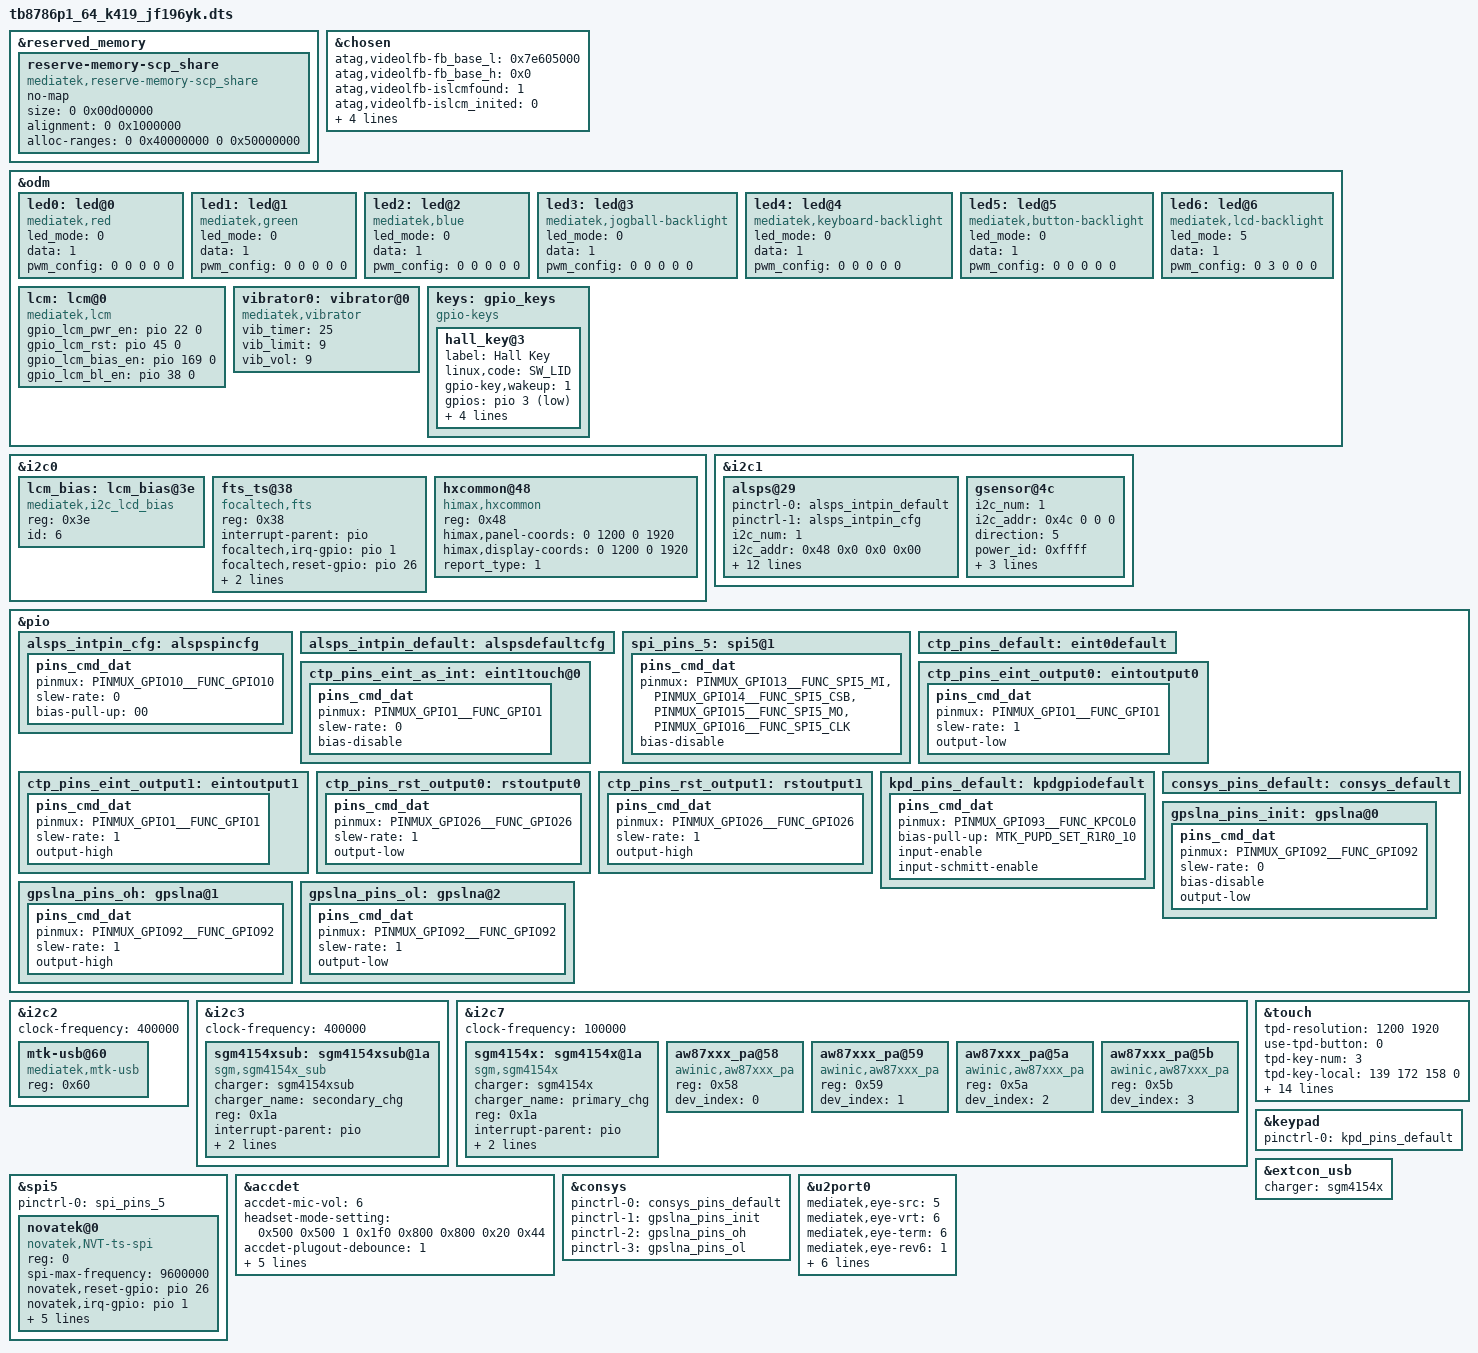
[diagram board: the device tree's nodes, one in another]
// SPDX-License-Identifier: GPL-2.0
/*
 * Copyright (c) 2019 MediaTek Inc.
 */

/dts-v1/;
/plugin/;
#include <dt-bindings/interrupt-controller/irq.h>
#include <dt-bindings/interrupt-controller/arm-gic.h>
#include <dt-bindings/pinctrl/mt6768-pinfunc.h>
#include <dt-bindings/input/input.h>

&reserved_memory {
	reserve-memory-scp_share {
		compatible = "mediatek,reserve-memory-scp_share";
		no-map;
		size = <0 0x00d00000>;
		alignment = <0 0x1000000>;
		alloc-ranges = <0 0x40000000 0 0x50000000>;
	};
};

/* chosen */
&chosen {

	atag,videolfb-fb_base_l = <0x7e605000>;
	atag,videolfb-fb_base_h = <0x0>;
	atag,videolfb-islcmfound = <1>;
	atag,videolfb-islcm_inited = <0>;
	atag,videolfb-fps= <6000>;
	atag,videolfb-vramSize= <0x017e8000>;
	atag,videolfb-lcmname=
		"hx83112b_fhdp_dsi_cmd_auo_rt5081_drv";
};

&odm {
	led0:led@0 {
		compatible = "mediatek,red";
		led_mode = <0>;
		data = <1>;
		pwm_config = <0 0 0 0 0>;
	};
	led1:led@1 {
		compatible = "mediatek,green";
		led_mode = <0>;
		data = <1>;
		pwm_config = <0 0 0 0 0>;
	};
	led2:led@2 {
		compatible = "mediatek,blue";
		led_mode = <0>;
		data = <1>;
		pwm_config = <0 0 0 0 0>;
	};
	led3:led@3 {
		compatible = "mediatek,jogball-backlight";
		led_mode = <0>;
		data = <1>;
		pwm_config = <0 0 0 0 0>;
	};
	led4:led@4 {
		compatible = "mediatek,keyboard-backlight";
		led_mode = <0>;
		data = <1>;
		pwm_config = <0 0 0 0 0>;
	};
	led5:led@5 {
		compatible = "mediatek,button-backlight";
		led_mode = <0>;
		data = <1>;
		pwm_config = <0 0 0 0 0>;
	};
	led6:led@6 {
		compatible = "mediatek,lcd-backlight";
		led_mode = <5>;
		data = <1>;
		pwm_config = <0 3 0 0 0>;
	};
	
	lcm: lcm@0{
		compatible = "mediatek,lcm";
		gpio_lcm_pwr_en = <&pio 22 0>; 			/*3.3V  1.8v*/
		gpio_lcm_rst = <&pio 45 0>;				//reset
		gpio_lcm_bias_en = <&pio 169 0>;
		gpio_lcm_bl_en = <&pio 38 0>;
		status = "okay";
	};
	
	vibrator0:vibrator@0 {
		compatible = "mediatek,vibrator";
		vib_timer = <25>;
		vib_limit = <9>;
		vib_vol= <9>;
	};
	
    keys: gpio_keys{         
		compatible = "gpio-keys";
		hall_key@3 {
			   label = "Hall Key";
			   linux,code = <SW_LID>;
			   gpio-key,wakeup = <1>;
			   gpios = <&pio 3 1>;
			   linux,input-type = <EV_SW>;
			   interrupt-parent = <&pio>;
			   interrupts = <3 IRQ_TYPE_EDGE_BOTH 3 0>;
			   debounce-interval = <20>;
		};
    };
};

&i2c0 {
	
	lcm_bias: lcm_bias@3e {
		compatible = "mediatek,i2c_lcd_bias";
		reg = <0x3e>;
		id = <6>;
		status = "okay";
	};
	
	fts_ts@38 {
		compatible = "focaltech,fts";
		reg = <0x38>;
		interrupt-parent = <&pio>;
		focaltech,irq-gpio = <&pio 1 0>;
		focaltech,reset-gpio = <&pio 26 0>;
		focaltech,max-touch-number = <10>;
		focaltech,display-coords =  <0 0 1200 1920>;
	};

	hxcommon@48 {
		compatible = "himax,hxcommon";
		reg = <0x48>;

		himax,panel-coords = <0 1200 0 1920>;
		himax,display-coords = <0 1200 0 1920>;

		status = "okay";
		report_type = <1>;
	};

};

&i2c1 {
	
	alsps@29 {
		pinctrl-names = "pin_default", "pin_cfg";
		pinctrl-0 = <&alsps_intpin_default>;
		pinctrl-1 = <&alsps_intpin_cfg>;
		status = "okay";
		/* customization */
		i2c_num = <1>;
		i2c_addr = <0x48 0x0 0x0 0x00>;
		polling_mode_ps = <0>;
		polling_mode_als = <1>;
		power_id = <0xffff>;
		power_vol = <0>;
		als_level =
			<0 1 1 7 15 15 100 1000 2000 3000
			6000 10000 14000 18000 20000>;
		als_value =
			<40 40 90 90 160 160 225 320 640 1280
			1280 2600 2600 2600 10240 10240>;
		ps_threshold_high = <900>;
		ps_threshold_low = <600>;
		is_batch_supported_ps = <0>;
		is_batch_supported_als = <0>;
	};	
	gsensor@4c{
		i2c_num = <1>;
		i2c_addr = <0x4c 0 0 0>;
		direction = <5>;
		power_id = <0xffff>;
		power_vol = <0>;
		firlen = <16>;
		is_batch_supported = <0>;
	};
	
};

&pio {
	alsps_intpin_cfg: alspspincfg {
	    pins_cmd_dat {
			pinmux = <PINMUX_GPIO10__FUNC_GPIO10>;
			slew-rate = <0>;
			bias-pull-up = <00>;
		};
	};

	alsps_intpin_default: alspsdefaultcfg {

	};
};

&i2c2 {
	clock-frequency = <400000>;

	mtk-usb@60 {
		compatible = "mediatek,mtk-usb";
		reg = <0x60>;
		status = "okay";
	};
};

&i2c3 {
	clock-frequency = <400000>;


	sgm4154xsub: sgm4154xsub@1a{
	  charger = <&sgm4154xsub>;
	  status = "okay";
	  compatible = "sgm,sgm4154x_sub";
	  charger_name = "secondary_chg";
	  reg = <0x1a>;
	  interrupt-parent = <&pio>;   
	  /*interrupts = <0 0>;*/						//irq num base on hardware design  
	  sgm,irq-gpio = <&pio 8 0>;        		 //irq num base on hardware design
	  sgm,chg-en-gpio = <&pio 6 0>;   		 //gpio num base on hardware design
	};
};

&i2c7 {
	clock-frequency = <100000>;

	sgm4154x: sgm4154x@1a{
	  charger = <&sgm4154x>;
	  status = "okay";
	  compatible = "sgm,sgm4154x";
	  charger_name = "primary_chg";
	  reg = <0x1a>;
	  interrupt-parent = <&pio>;
	  /*interrupts = <0 0>;*/						//irq num base on hardware design  
	  sgm,irq-gpio = <&pio 20 0>;        		 //irq num base on hardware design
	  sgm,chg-en-gpio = <&pio 166 0>;   		 //gpio num base on hardware design
	};
	
	aw87xxx_pa@58 {
        compatible = "awinic,aw87xxx_pa";
        reg = <0x58>;
        dev_index = < 0 >;
        status = "okay";
    };

    aw87xxx_pa@59 {
        compatible = "awinic,aw87xxx_pa";
        reg = <0x59>;
        dev_index = < 1 >;
        status = "okay";
    };

    aw87xxx_pa@5a {
        compatible = "awinic,aw87xxx_pa";
        reg = <0x5a>;
        dev_index = < 2 >;
        status = "okay";
    };
    aw87xxx_pa@5b {
        compatible = "awinic,aw87xxx_pa";
        reg = <0x5b>;
        dev_index = < 3 >;
        status = "okay";
    };

};

&pio{
    spi_pins_5:spi5@1{
        pins_cmd_dat{
            pinmux = <PINMUX_GPIO13__FUNC_SPI5_MI>,
                     <PINMUX_GPIO14__FUNC_SPI5_CSB>,
                     <PINMUX_GPIO15__FUNC_SPI5_MO>,
                     <PINMUX_GPIO16__FUNC_SPI5_CLK>;
                     bias-disable;
        };
    };
};

/* &spi5 {
    #address-cells = <1>;
    #size-cells = <0>;
    status = "okay";

    himax_touch@0 {
        compatible = "himax,hxcommon";
        reg = <0>;
        spi-max-frequency = <10000000>;
		himax,irq-gpio = <&pio 1 0>;
		himax,rst-gpio = <&pio 26 0>;
		himax,panel-coords = <0 1200 0 2000>;
    };

}; */   /* HX83102J_SPI */

&spi5 {
    #address-cells = <1>;
    #size-cells = <0>;
    pinctrl-names = "default";
    pinctrl-0 = <&spi_pins_5>;
    status = "okay";
	
    novatek@0{
        compatible = "novatek,NVT-ts-spi";
        reg = <0>;
        spi-max-frequency = <9600000>;

        novatek,reset-gpio = <&pio 26 0x0>;
        novatek,irq-gpio = <&pio 1 0x0>;

        novatek,pen-support;
        novatek,wgp-stylus;

        novatek,swrst-n8-addr = <0x03F0FE>;
        novatek,spi-rd-fast-addr = <0x03F310>;
		
		novatek,panel-coords = <1200 1920>;
    };

};   /* NT36523_SPI */


	
/* TOUCH start */
&touch {
	tpd-resolution = <1200 1920>;
	use-tpd-button = <0>;
	tpd-key-num = <3>;
	tpd-key-local= <139 172 158 0>;
	tpd-key-dim-local = <90 883 100 40 230
				 883 100 40 370 883 100 40 0 0 0 0>;
	tpd-max-touch-num = <10>;
	tpd-filter-enable = <0>;
	tpd-filter-pixel-density = <106>;
	tpd-filter-custom-prameters = <0 0 0 0 0 0 0 0 0 0 0 0>;
	tpd-filter-custom-speed = <0 0 0>;
	pinctrl-names = "default", "state_eint_as_int", "state_eint_output0",
		"state_eint_output1", "state_rst_output0", "state_rst_output1";
	pinctrl-0 = <&ctp_pins_default>;
	pinctrl-1 = <&ctp_pins_eint_as_int>;
	pinctrl-2 = <&ctp_pins_eint_output0>;
	pinctrl-3 = <&ctp_pins_eint_output1>;
	pinctrl-4 = <&ctp_pins_rst_output0>;
	pinctrl-5 = <&ctp_pins_rst_output1>;
	status = "okay";
};
&pio {

	ctp_pins_default: eint0default {
	};
	ctp_pins_eint_as_int: eint1touch@0 {
		pins_cmd_dat {
			pinmux = <PINMUX_GPIO1__FUNC_GPIO1>;
			slew-rate = <0>;
			bias-disable;
		};
	};
	ctp_pins_eint_output0: eintoutput0 {
		pins_cmd_dat {
			pinmux = <PINMUX_GPIO1__FUNC_GPIO1>;
			slew-rate = <1>;
			output-low;
		};
	};
	ctp_pins_eint_output1: eintoutput1 {
		pins_cmd_dat {
			pinmux = <PINMUX_GPIO1__FUNC_GPIO1>;
			slew-rate = <1>;
			output-high;
		};
	};
	ctp_pins_rst_output0: rstoutput0 {
		pins_cmd_dat {
			pinmux = <PINMUX_GPIO26__FUNC_GPIO26>;
			slew-rate = <1>;
			output-low;
		};
	};
	ctp_pins_rst_output1: rstoutput1 {
		pins_cmd_dat {
			pinmux = <PINMUX_GPIO26__FUNC_GPIO26>;
			slew-rate = <1>;
			output-high;
		};
	};
};
/* TOUCH end */

/* accdet start */
&accdet {
	/* accdet micbias voltage: 0x07,2.7v;0x05,2.5v;0x02,1.9v */
	accdet-mic-vol = <6>;
	headset-mode-setting = <0x500 0x500 1 0x1f0 0x800 0x800 0x20 0x44>;
	accdet-plugout-debounce = <1>;
	/*1:ACC mode, 2:low cost without in bias, 6:low cost with in bias*/
	accdet-mic-mode = <1>;
	/* eint_level_trigger: 8,LEVEL_LOW(DEF) ;4,LV_HIGH;others,LV_LOW */
	headset-eint-level-pol = <8>;
	/*0--MD_MAX--UP_MAX--DW_MAX*/
	headset-three-key-threshold = <0 80 220 400>;
	headset-three-key-threshold-CDD = <0 121 192 600>;
	/*0--MD_MAX--VOICE_MAX--UP_MAX--DW_MAX*/
	headset-four-key-threshold = <0 58 121 192 400>;
	status = "okay";
};
/* accdet end */

/* keypad start */
&keypad {
	pinctrl-names = "default";
	pinctrl-0 = <&kpd_pins_default>;
};

&pio {
	kpd_pins_default: kpdgpiodefault {
		pins_cmd_dat {
			pinmux = <PINMUX_GPIO93__FUNC_KPCOL0>;
			bias-pull-up = <MTK_PUPD_SET_R1R0_10>;
			input-enable;
			input-schmitt-enable;
		};
	};
};
/* keypad end */


/* CONSYS GPIO standardization */
&pio {
	consys_pins_default: consys_default {
	};
	gpslna_pins_init: gpslna@0 {
		pins_cmd_dat {
			pinmux = <PINMUX_GPIO92__FUNC_GPIO92>;
			slew-rate = <0>;
			bias-disable;
			output-low;
		};
	};
	gpslna_pins_oh: gpslna@1 {
		pins_cmd_dat {
			pinmux = <PINMUX_GPIO92__FUNC_GPIO92>;
			slew-rate = <1>;
			output-high;
		};
	};
	gpslna_pins_ol: gpslna@2 {
		pins_cmd_dat {
			pinmux = <PINMUX_GPIO92__FUNC_GPIO92>;
			slew-rate = <1>;
			output-low;
		};
	};
};
&consys {
	pinctrl-names = "default", "gps_lna_state_init",
		"gps_lna_state_oh", "gps_lna_state_ol";
	pinctrl-0 = <&consys_pins_default>;
	pinctrl-1 = <&gpslna_pins_init>;
	pinctrl-2 = <&gpslna_pins_oh>;
	pinctrl-3 = <&gpslna_pins_ol>;
	status = "okay";
};
/* CONSYS end */


/* DISPSYS GPIO standardization end*/

&extcon_usb {
	charger = <&sgm4154x>;
};

&u2port0 {
	mediatek,eye-src = <5>;
	mediatek,eye-vrt = <6>;
	mediatek,eye-term = <6>;
	mediatek,eye-rev6 = <1>;
	mediatek,eye-disc = <10>;
	mediatek,host-eye-src = <5>;
	mediatek,host-eye-vrt = <6>;
	mediatek,host-eye-term = <6>;
	mediatek,host-eye-rev6 = <1>;
	mediatek,host-eye-disc = <10>;
};
			
#include <tb8786p1_64_k419/cust.dtsi>
#include "mediatek/tcpc_config-husb311.dtsi"
#include "mediatek/cust_mt6768_camera.dtsi"
/*End of this file, DO NOT ADD ANYTHING HERE*/
